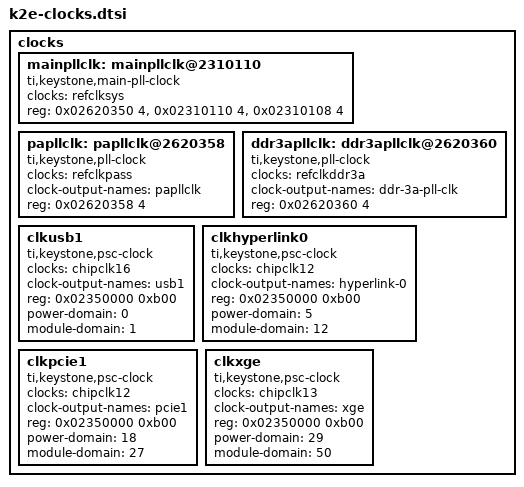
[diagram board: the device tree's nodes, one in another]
/*
 * Copyright 2014 Texas Instruments, Inc.
 *
 * Keystone 2 Edison SoC specific device tree
 *
 * This program is free software; you can redistribute it and/or modify
 * it under the terms of the GNU General Public License version 2 as
 * published by the Free Software Foundation.
 */

clocks {
	mainpllclk: mainpllclk@2310110 {
		#clock-cells = <0>;
		compatible = "ti,keystone,main-pll-clock";
		clocks = <&refclksys>;
		reg = <0x02620350 4>, <0x02310110 4>, <0x02310108 4>;
		reg-names = "control", "multiplier", "post-divider";
	};

	papllclk: papllclk@2620358 {
		#clock-cells = <0>;
		compatible = "ti,keystone,pll-clock";
		clocks = <&refclkpass>;
		clock-output-names = "papllclk";
		reg = <0x02620358 4>;
		reg-names = "control";
	};

	ddr3apllclk: ddr3apllclk@2620360 {
		#clock-cells = <0>;
		compatible = "ti,keystone,pll-clock";
		clocks = <&refclkddr3a>;
		clock-output-names = "ddr-3a-pll-clk";
		reg = <0x02620360 4>;
		reg-names = "control";
	};

	clkusb1: clkusb1 {
		#clock-cells = <0>;
		compatible = "ti,keystone,psc-clock";
		clocks = <&chipclk16>;
		clock-output-names = "usb1";
		reg = <0x02350000 0xb00>;
		power-domain = <0>;
		module-domain = <1>;
	};

	clkhyperlink0: clkhyperlink0 {
		#clock-cells = <0>;
		compatible = "ti,keystone,psc-clock";
		clocks = <&chipclk12>;
		clock-output-names = "hyperlink-0";
		reg = <0x02350000 0xb00>;
		power-domain = <5>;
		module-domain = <12>;
	};

	clkpcie1: clkpcie1 {
		#clock-cells = <0>;
		compatible = "ti,keystone,psc-clock";
		clocks = <&chipclk12>;
		clock-output-names = "pcie1";
		reg = <0x02350000 0xb00>;
		power-domain = <18>;
		module-domain = <27>;
	};

	clkxge: clkxge {
		#clock-cells = <0>;
		compatible = "ti,keystone,psc-clock";
		clocks = <&chipclk13>;
		clock-output-names = "xge";
		reg = <0x02350000 0xb00>;
		power-domain = <29>;
		module-domain = <50>;
	};
};
